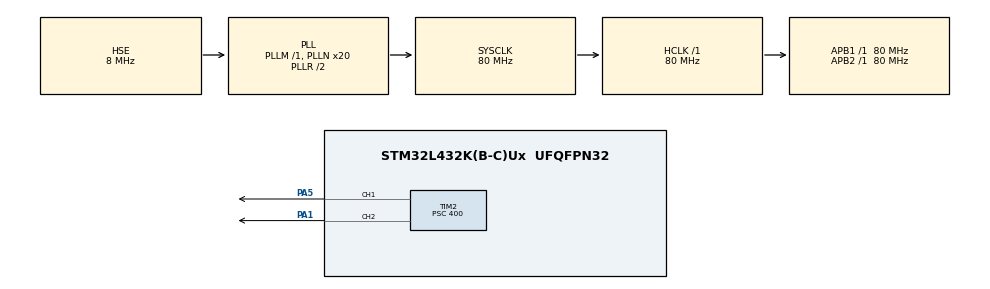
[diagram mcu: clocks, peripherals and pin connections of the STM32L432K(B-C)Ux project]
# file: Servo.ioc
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Mcu.Family=STM32L4
Mcu.Name=STM32L432K(B-C)Ux
Mcu.Package=UFQFPN32
NVIC.PriorityGroup=NVIC_PRIORITYGROUP_4
PA0.Mode=HSE-External-Clock-Source-for-LittleOrca
PA0.Signal=RCC_CK_IN
PA1.Signal=S_TIM2_CH2
PA13\ (JTMS-SWDIO).Mode=Serial_Wire
PA13\ (JTMS-SWDIO).Signal=SYS_JTMS-SWDIO
PA14\ (JTCK-SWCLK).Mode=Serial_Wire
PA14\ (JTCK-SWCLK).Signal=SYS_JTCK-SWCLK
PA5.Signal=S_TIM2_CH1
PC14-OSC32_IN\ (PC14).Mode=LSE-External-Oscillator
PC14-OSC32_IN\ (PC14).Signal=RCC_OSC32_IN
PC15-OSC32_OUT\ (PC15).Mode=LSE-External-Oscillator
PC15-OSC32_OUT\ (PC15).Signal=RCC_OSC32_OUT
ProjectManager.HeapSize=0x200
ProjectManager.StackSize=0x400
ProjectManager.TargetToolchain=MDK-ARM V5
RCC.ADCFreq_Value=32000000
RCC.AHBFreq_Value=80000000
RCC.APB1Freq_Value=80000000
RCC.APB1TimFreq_Value=80000000
RCC.APB2Freq_Value=80000000
RCC.APB2TimFreq_Value=80000000
RCC.CortexFreq_Value=80000000
RCC.HCLKFreq_Value=80000000
RCC.HSE_VALUE=8000000
RCC.HSI48_VALUE=48000000
RCC.HSI_VALUE=16000000
RCC.MSI_VALUE=4000000
RCC.PLLN=20
RCC.PLLSourceVirtual=RCC_PLLSOURCE_HSE
RCC.SYSCLKFreq_VALUE=80000000
RCC.SYSCLKSource=RCC_SYSCLKSOURCE_PLLCLK
RCC.USBFreq_Value=32000000
RCC.VCOOutputFreq_Value=160000000
SH.S_TIM2_CH1.0=TIM2_CH1,PWM Generation1 CH1
SH.S_TIM2_CH2.0=TIM2_CH2,PWM Generation2 CH2
TIM2.Channel-PWM\ Generation1\ CH1=TIM_CHANNEL_1
TIM2.Channel-PWM\ Generation2\ CH2=TIM_CHANNEL_2
TIM2.Period=200
TIM2.Prescaler=400
board=custom

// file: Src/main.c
/* USER CODE BEGIN Header */
/**
  ******************************************************************************
  * @file           : main.c
  * @brief          : Main program body
  ******************************************************************************
  * @attention
  *
  * <h2><center>&copy; Copyright (c) 2019 STMicroelectronics.
  * All rights reserved.</center></h2>
  *
  * This software component is licensed by ST under BSD 3-Clause license,
  * the "License"; You may not use this file except in compliance with the
  * License. You may obtain a copy of the License at:
  *                        opensource.org/licenses/BSD-3-Clause
  *
  ******************************************************************************
  */
/* USER CODE END Header */

#include "main.h"
#include "tim.h"
#include "gpio.h"

/* USER CODE BEGIN Includes */
#include "servo.h"
/* USER CODE END Includes */

/* USER CODE BEGIN PV */
int i=0;
int j=0;
/* USER CODE END PV */

void SystemClock_Config(void);

int main(void)
{

  /* MCU Configuration--------------------------------------------------------*/

  /* Reset of all peripherals, Initializes the Flash interface and the Systick. */
  HAL_Init();

  /* Configure the system clock */
  SystemClock_Config();

  /* Initialize all configured peripherals */
  MX_GPIO_Init();
  MX_TIM2_Init();
  /* USER CODE BEGIN 2 */
	Servo_Init();
  /* USER CODE END 2 */

  /* Infinite loop */
  while (1)
  {

    /* USER CODE BEGIN 3 */
//		Servo_Control_X(10.5);
//		HAL_Delay(1000);
//		Servo_Control_X(270);
//		HAL_Delay(1000);
//		Servo_Control_X(30.5);
//		HAL_Delay(1000);
		TIM2->CCR1=100;
//		Pan_Tilt(95,45);
//		HAL_Delay(1000);
//		Pan_Tilt(150,80);
//		HAL_Delay(1000);
  }
  /* USER CODE END 3 */
}

void SystemClock_Config(void)
{
  RCC_OscInitTypeDef RCC_OscInitStruct = {0};
  RCC_ClkInitTypeDef RCC_ClkInitStruct = {0};

  /** Initializes the CPU, AHB and APB busses clocks
  */
  RCC_OscInitStruct.OscillatorType = RCC_OSCILLATORTYPE_HSE;
  RCC_OscInitStruct.HSEState = RCC_HSE_BYPASS;
  RCC_OscInitStruct.PLL.PLLState = RCC_PLL_ON;
  RCC_OscInitStruct.PLL.PLLSource = RCC_PLLSOURCE_HSE;
  RCC_OscInitStruct.PLL.PLLM = 1;
  RCC_OscInitStruct.PLL.PLLN = 20;
  RCC_OscInitStruct.PLL.PLLP = RCC_PLLP_DIV7;
  RCC_OscInitStruct.PLL.PLLQ = RCC_PLLQ_DIV2;
  RCC_OscInitStruct.PLL.PLLR = RCC_PLLR_DIV2;
  if (HAL_RCC_OscConfig(&RCC_OscInitStruct) != HAL_OK)
  {
    Error_Handler();
  }
  /** Initializes the CPU, AHB and APB busses clocks
  */
  RCC_ClkInitStruct.ClockType = RCC_CLOCKTYPE_HCLK|RCC_CLOCKTYPE_SYSCLK
                              |RCC_CLOCKTYPE_PCLK1|RCC_CLOCKTYPE_PCLK2;
  RCC_ClkInitStruct.SYSCLKSource = RCC_SYSCLKSOURCE_PLLCLK;
  RCC_ClkInitStruct.AHBCLKDivider = RCC_SYSCLK_DIV1;
  RCC_ClkInitStruct.APB1CLKDivider = RCC_HCLK_DIV1;
  RCC_ClkInitStruct.APB2CLKDivider = RCC_HCLK_DIV1;

  if (HAL_RCC_ClockConfig(&RCC_ClkInitStruct, FLASH_LATENCY_4) != HAL_OK)
  {
    Error_Handler();
  }
  /** Configure the main internal regulator output voltage
  */
  if (HAL_PWREx_ControlVoltageScaling(PWR_REGULATOR_VOLTAGE_SCALE1) != HAL_OK)
  {
    Error_Handler();
  }
}

void Error_Handler(void)
{
}

/************************ (C) COPYRIGHT STMicroelectronics *****END OF FILE****/
